# AST1080 register map
File version: 1.0
CPU: CM4 r0p1, little endian, MPU, FPU, 4 interrupt priority bits, 256 interrupts
Registers are 32-bit, read-write, reset 0x0 unless marked. A register's access mark holds for its fields unless they carry their own. Offsets are from the block's base; [hi:lo] are bit positions; {n}, {i} and the like mark numbered series.

## scu (part 1 of 2)
Base 0x74C02000
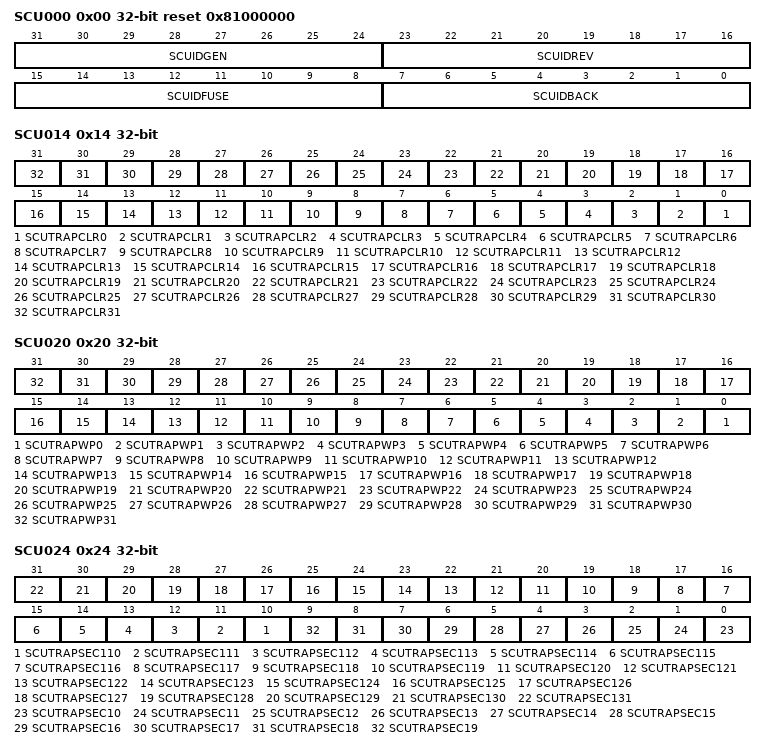
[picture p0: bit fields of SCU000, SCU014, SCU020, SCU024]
0x00 SCU000 reset 0x81000000 — Silicon Revision ID Register
  [31:24] SCUIDGEN ro, [23:16] SCUIDREV ro, [15:8] SCUIDFUSE ro, [7:0] SCUIDBACK ro
0x10 SCU010 — Hardware/OTP Strap 1 Register
  [n] SCUTRAP{n} (n=0..31)
  [8] SCUTRAP81 — SCU_TRAP_8
0x14 SCU014 — Hareware/OTP Strap Clear 1 Register
  [n] SCUTRAPCLR{n} (n=0..31)
0x20 SCU020 — Hardware/OTP Strap Write Protection 1 Register
  [n] SCUTRAPWP{n} (n=0..31)
0x24 SCU024 — Hardware/OTP Strap Secure Control Register 1
  [n-100] SCUTRAPSEC{n} (n=110..131), [n-10] SCUTRAPSEC{n} (n=10..19)
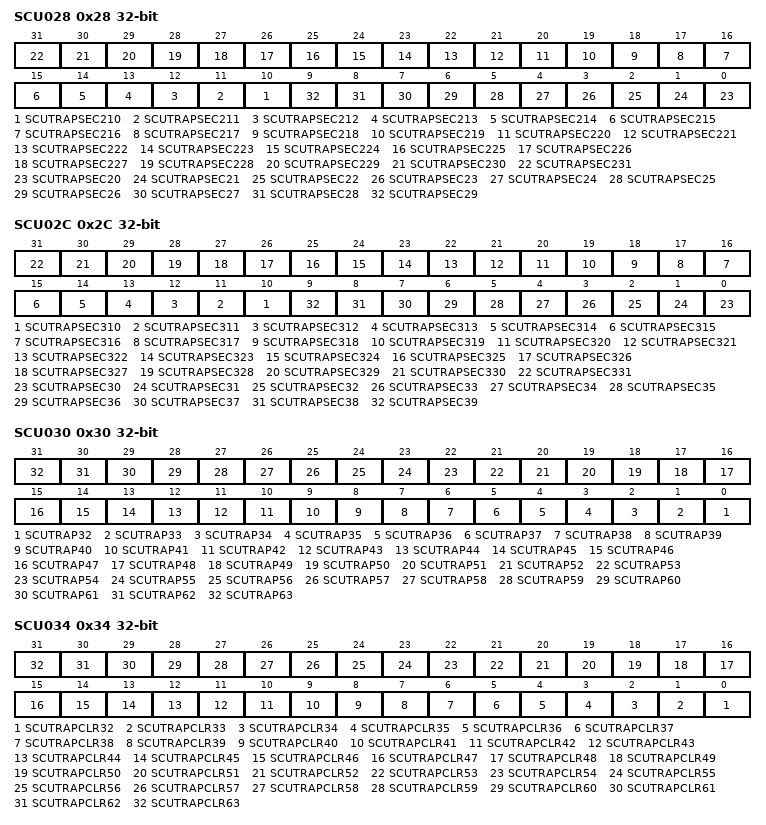
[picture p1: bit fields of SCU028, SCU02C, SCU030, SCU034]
0x28 SCU028 — Hardware/OTP Strap Secure Control Register 2
  [n-200] SCUTRAPSEC{n} (n=210..231), [n-20] SCUTRAPSEC{n} (n=20..29)
0x2C SCU02C — Hardware/OTP Strap Secure Control Register 3
  [n-300] SCUTRAPSEC{n} (n=310..331), [n-30] SCUTRAPSEC{n} (n=30..39)
0x30 SCU030 — Hardware/OTP Strap 2 Register
  [n-32] SCUTRAP{n} (n=32..63)
0x34 SCU034 — Hareware/OTP Strap Clear 2 Register
  [n-32] SCUTRAPCLR{n} (n=32..63)
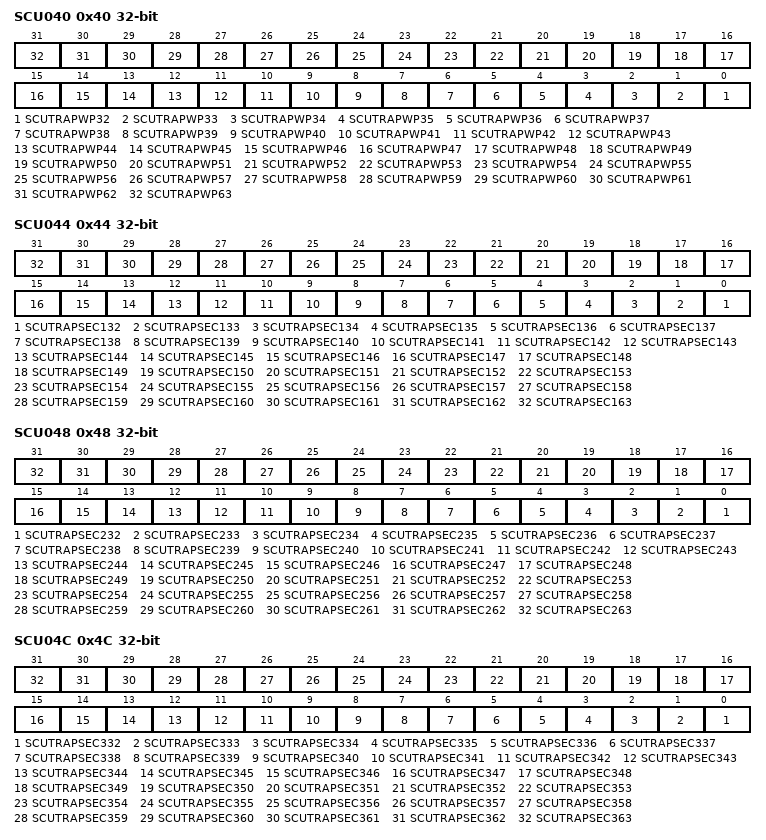
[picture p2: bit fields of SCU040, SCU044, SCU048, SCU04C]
0x40 SCU040 — Hardware/OTP Strap Write Protection 2 Register
  [n-32] SCUTRAPWP{n} (n=32..63)
0x44 SCU044 — Hardware/OTP Strap 2 Secure Control Register 1
  [n-132] SCUTRAPSEC{n} (n=132..163)
0x48 SCU048 — Hardware/OTP Strap 2 Secure Control Register 2
  [n-232] SCUTRAPSEC{n} (n=232..263)
0x4C SCU04C — Hardware/OTP Strap 2 Secure Control Register 3
  [n-332] SCUTRAPSEC{n} (n=332..363)
0x50 SCU050 — Hardware/OTP Strap 3 Register
  [n-64] SCUTRAP{n} (n=64..95)
  [20] SCUTRAP841 — SCU_TRAP_84
  [19] SCUTRAP831 — SCU_TRAP_83
  [18] SCUTRAP821 — SCU_TRAP_82
  [17] SCUTRAP811 — SCU_TRAP_81
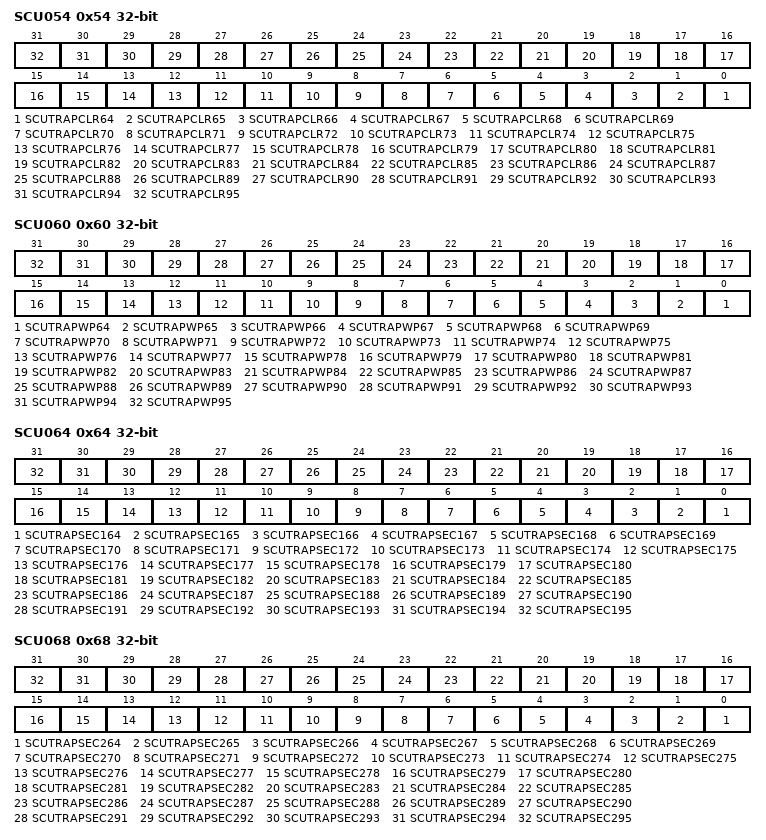
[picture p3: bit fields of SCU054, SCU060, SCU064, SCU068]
0x54 SCU054 — Hareware/OTP Strap Clear 3 Register
  [n-64] SCUTRAPCLR{n} (n=64..95)
0x60 SCU060 — Hardware/OTP Strap Write Protection 3 Register
  [n-64] SCUTRAPWP{n} (n=64..95)
0x64 SCU064 — Hardware/OTP Strap 3 Secure Control Register 1
  [n-164] SCUTRAPSEC{n} (n=164..195)
0x68 SCU068 — Hardware/OTP Strap 3 Secure Control Register 2
  [n-264] SCUTRAPSEC{n} (n=264..295)
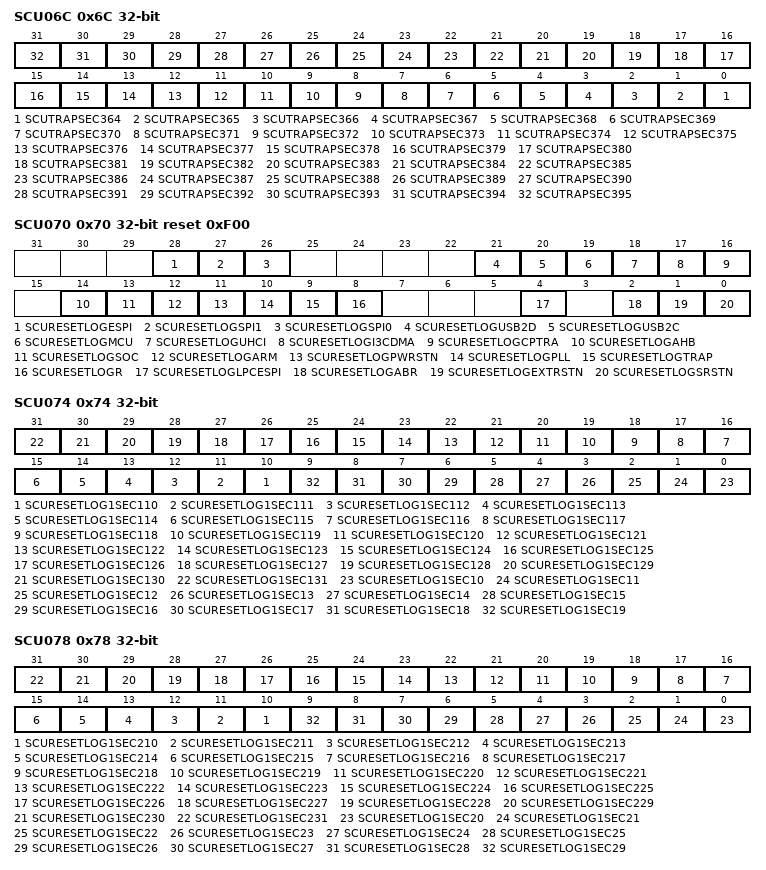
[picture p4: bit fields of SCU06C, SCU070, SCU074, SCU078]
0x6C SCU06C — Hardware/OTP Strap 3 Secure Control Register 3
  [n-364] SCUTRAPSEC{n} (n=364..395)
0x70 SCU070 reset 0xF00 (reset mask 0xC3F7F17) — System Reset Event Log Set 1 Register
  [28] SCURESETLOGESPI, [27] SCURESETLOGSPI1, [26] SCURESETLOGSPI0, [21] SCURESETLOGUSB2D, [20] SCURESETLOGUSB2C, [19] SCURESETLOGMCU, [18] SCURESETLOGUHCI, [17] SCURESETLOGI3CDMA, [16] SCURESETLOGCPTRA, [14] SCURESETLOGAHB, [13] SCURESETLOGSOC, [12] SCURESETLOGARM, [11] SCURESETLOGPWRSTN, [10] SCURESETLOGPLL, [9] SCURESETLOGTRAP, [8] SCURESETLOGR, [4] SCURESETLOGLPCESPI, [2] SCURESETLOGABR, [1] SCURESETLOGEXTRSTN, [0] SCURESETLOGSRSTN
0x74 SCU074 — System Reset Event Log Set 1 Secure Register 1
  [n-100] SCURESETLOG1SEC{n} (n=110..131), [n-10] SCURESETLOG1SEC{n} (n=10..19)
0x78 SCU078 — System Reset Event Log Set 1 Secure Register 2
  [n-200] SCURESETLOG1SEC{n} (n=210..231), [n-20] SCURESETLOG1SEC{n} (n=20..29)
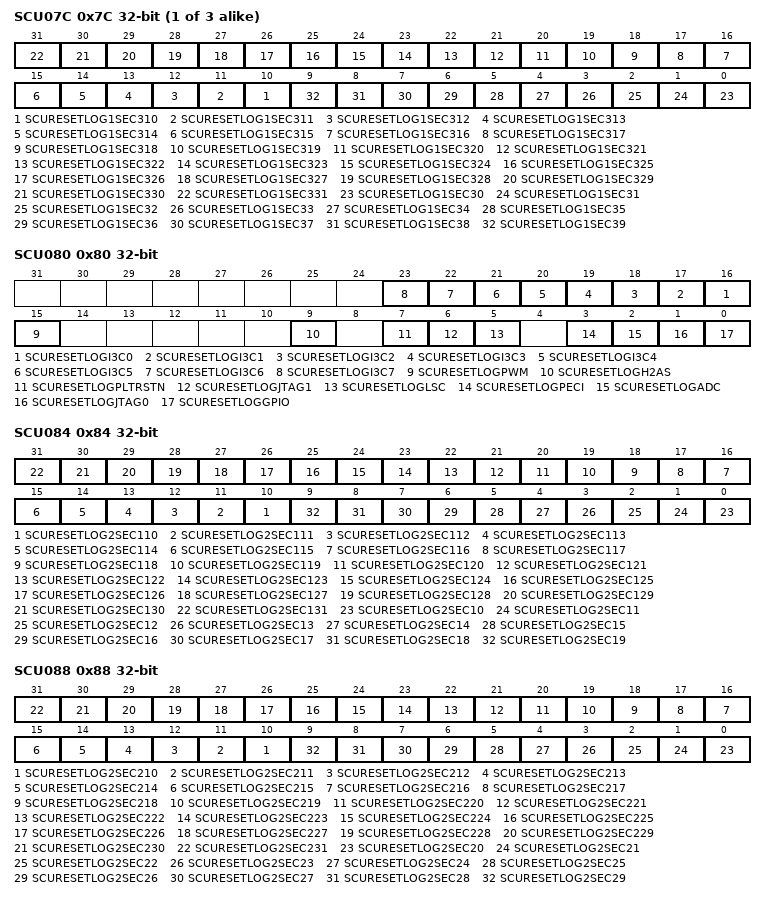
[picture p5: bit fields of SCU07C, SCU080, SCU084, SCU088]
{0xC+0x10*i} SCU{i:02}C (i=7..9) — System Reset Event Log Set {i-6} Secure Register 3
  [n-300] SCURESETLOG{i-6}SEC{n} (n=310..331), [n-30] SCURESETLOG{i-6}SEC{n} (n=30..39)
0x80 SCU080 (reset mask 0xFF0067) — System Reset Event Log Set 2 Register
  [n+16] SCURESETLOGI3C{n} (n=0..7), [15] SCURESETLOGPWM, [9] SCURESETLOGH2AS, [7] SCURESETLOGPLTRSTN, [6] SCURESETLOGJTAG1, [5] SCURESETLOGLSC, [3] SCURESETLOGPECI, [2] SCURESETLOGADC, [1] SCURESETLOGJTAG0, [0] SCURESETLOGGPIO
0x84 SCU084 — System Reset Event Log Set 2 Secure Register 1
  [n-100] SCURESETLOG2SEC{n} (n=110..131), [n-10] SCURESETLOG2SEC{n} (n=10..19)
0x88 SCU088 — System Reset Event Log Set 2 Secure Register 2
  [n-200] SCURESETLOG2SEC{n} (n=210..231), [n-20] SCURESETLOG2SEC{n} (n=20..29)
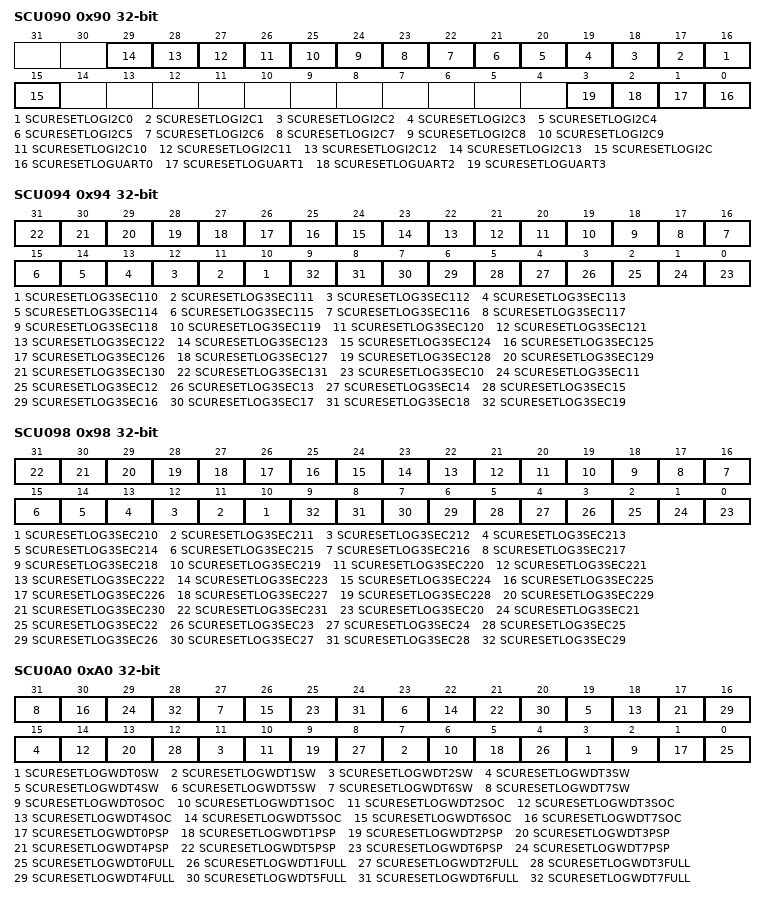
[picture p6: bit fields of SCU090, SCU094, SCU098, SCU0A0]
0x90 SCU090 — System Reset Event Log Set 3 Register
  [n+16] SCURESETLOGI2C{n} (n=0..13), [15] SCURESETLOGI2C, [n] SCURESETLOGUART{n} (n=0..3)
0x94 SCU094 — System Reset Event Log Set 3 Secure Register 1
  [n-100] SCURESETLOG3SEC{n} (n=110..131), [n-10] SCURESETLOG3SEC{n} (n=10..19)
0x98 SCU098 — System Reset Event Log Set 3 Secure Register 2
  [n-200] SCURESETLOG3SEC{n} (n=210..231), [n-20] SCURESETLOG3SEC{n} (n=20..29)
0xA0 SCU0A0 — System Reset Event Log Set 4 Register
  [4n+3] SCURESETLOGWDT{n}SW (n=0..7), [4n+2] SCURESETLOGWDT{n}SOC (n=0..7), [4n+1] SCURESETLOGWDT{n}PSP (n=0..7), [4n] SCURESETLOGWDT{n}FULL (n=0..7)
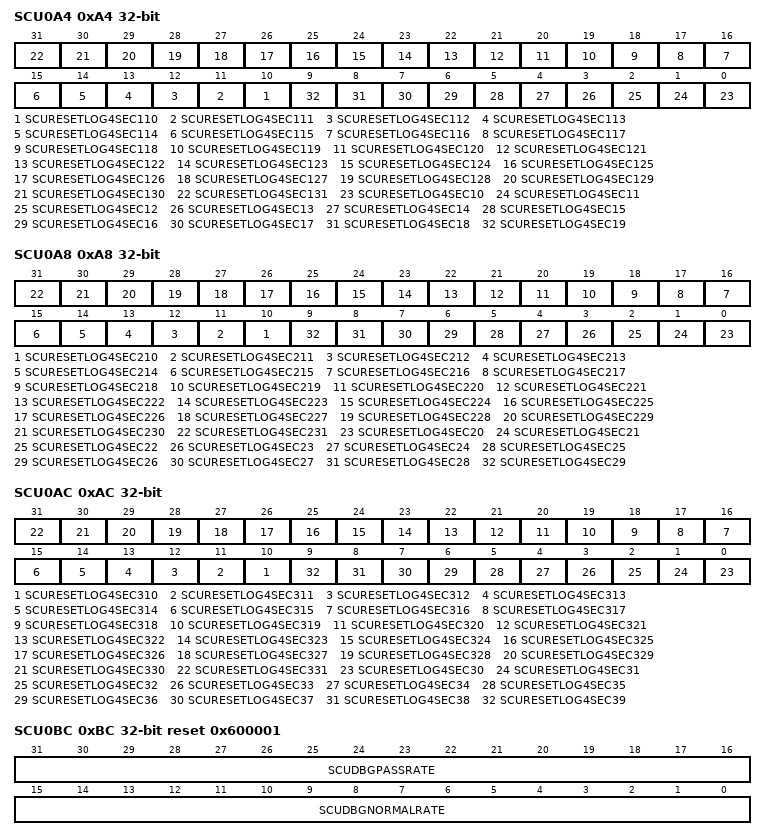
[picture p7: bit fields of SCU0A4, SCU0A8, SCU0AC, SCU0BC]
0xA4 SCU0A4 — System Reset Event Log Set 4 Secure Register 1
  [n-100] SCURESETLOG4SEC{n} (n=110..131), [n-10] SCURESETLOG4SEC{n} (n=10..19)
0xA8 SCU0A8 — System Reset Event Log Set 4 Secure Register 2
  [n-200] SCURESETLOG4SEC{n} (n=210..231), [n-20] SCURESETLOG4SEC{n} (n=20..29)
0xAC SCU0AC — System Reset Event Log Set 4 Secure Register 3
  [n-300] SCURESETLOG4SEC{n} (n=310..331), [n-30] SCURESETLOG4SEC{n} (n=30..39)
0xBC SCU0BC reset 0x600001 — Debug UART Baudrate
  [31:16] SCUDBGPASSRATE, [15:0] SCUDBGNORMALRATE
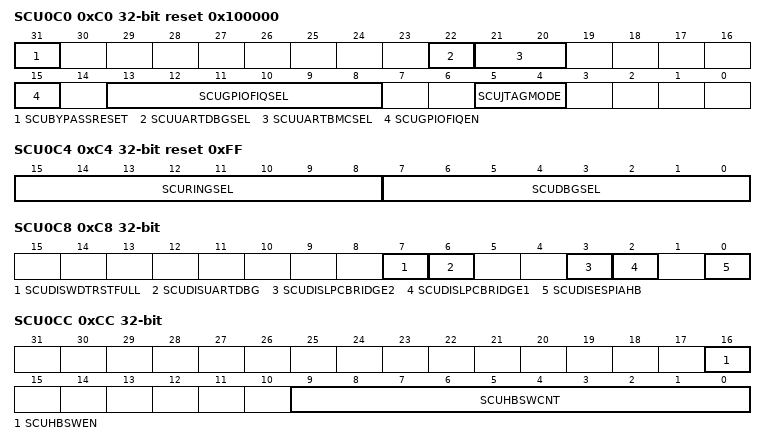
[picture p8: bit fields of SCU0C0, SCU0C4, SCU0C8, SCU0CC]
0xC0 SCU0C0 reset 0x100000 — Misc. Control Set 1 Register
  [31] SCUBYPASSRESET, [22] SCUUARTDBGSEL, [21:20] SCUUARTBMCSEL, [15] SCUGPIOFIQEN, [13:8] SCUGPIOFIQSEL, [5:4] SCUJTAGMODE
0xC4 SCU0C4 reset 0xFF — Debug Selection Register
  [15:8] SCURINGSEL, [7:0] SCUDBGSEL
0xC8 SCU0C8 — Debug Disable Register
  [7] SCUDISWDTRSTFULL, [6] SCUDISUARTDBG, [3] SCUDISLPCBRIDGE2, [2] SCUDISLPCBRIDGE1, [0] SCUDISESPIAHB
0xCC SCU0CC — HeartBeat Control Register
  [16] SCUHBSWEN, [9:0] SCUHBSWCNT
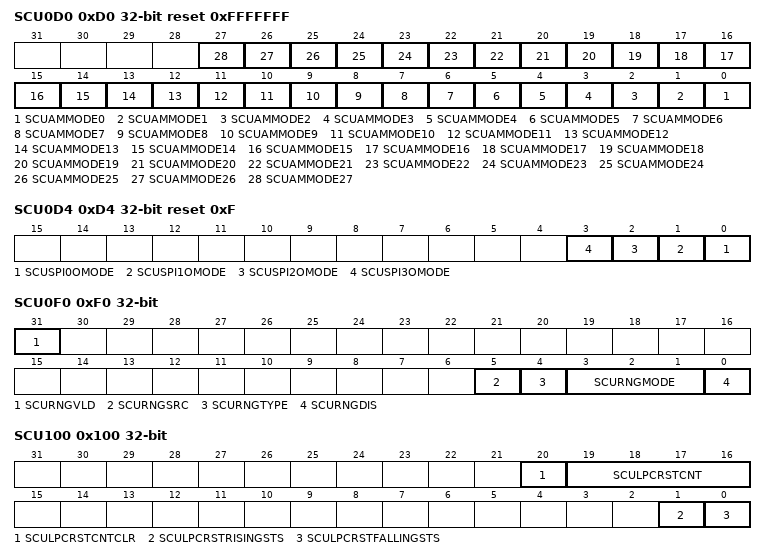
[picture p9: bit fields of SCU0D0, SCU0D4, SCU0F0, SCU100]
0xD0 SCU0D0 reset 0xFFFFFFF — Analog Mux Mode Register
  [n] SCUAMMODE{n} (n=0..27)
0xD4 SCU0D4 reset 0xF — SPI Mode Register
  [n] SCUSPI{n}OMODE (n=0..3)
0xF0 SCU0F0 — Random Number Generator Control Register
  [31] SCURNGVLD ro, [5] SCURNGSRC, [4] SCURNGTYPE, [3:1] SCURNGMODE, [0] SCURNGDIS
0xF4 SCU0F4 — Random Number Generator Data Register
  [31:0] SCURNGDAT ro
0x100 SCU100 — Interrupt Status Register
  [20] SCULPCRSTCNTCLR, [19:16] SCULPCRSTCNT ro, [1] SCULPCRSTRISINGSTS, [0] SCULPCRSTFALLINGSTS
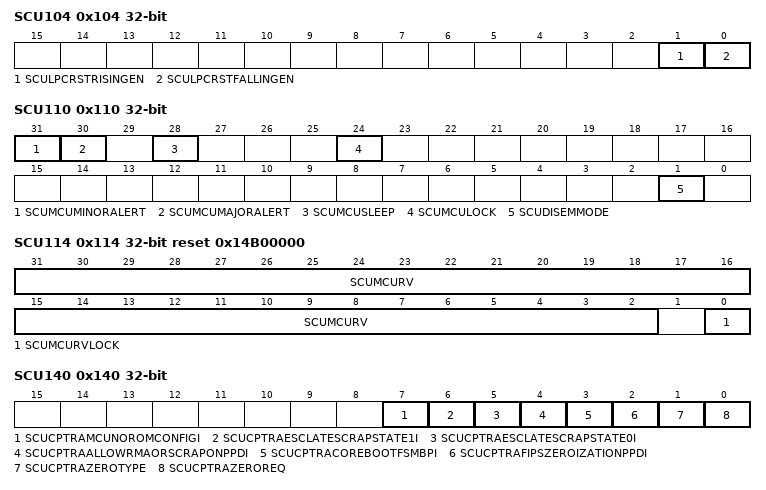
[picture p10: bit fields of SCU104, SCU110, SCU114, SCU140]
0x104 SCU104 — Interrupt Control Register
  [1] SCULPCRSTRISINGEN, [0] SCULPCRSTFALLINGEN
0x110 SCU110 — MCU Control and Status Register
  [31] SCUMCUMINORALERT ro, [30] SCUMCUMAJORALERT ro, [28] SCUMCUSLEEP ro, [24] SCUMCULOCK, [1] SCUDISEMMODE
0x114 SCU114 reset 0x14B00000 — MCU Reset Vector
  [31:2] SCUMCURV, [0] SCUMCURVLOCK
0x120 SCU120 — CPTRA Page Register 0
  [31:16] SCUCPTRAPAGEADR0
0x124 SCU124 — CPTRA Page Register 1
  [31:16] SCUCPTRAPAGEADR1
0x128 SCU128 — CPTRA Page Register 2
  [31:16] SCUCPTRAPAGEADR2
0x12C SCU12C — CPTRA Page Register 3
  [31:16] SCUCPTRAPAGEADR3
0x130 SCU130 — CPTRA Page Register 4
  [31:16] SCUCPTRAPAGEADR4
0x134 SCU134 — CPTRA Page Register 5
  [31:16] SCUCPTRAPAGEADR5
0x140 SCU140 — Caliptra Config Register 0
  [7] SCUCPTRAMCUNOROMCONFIGI, [6] SCUCPTRAESCLATESCRAPSTATE1I, [5] SCUCPTRAESCLATESCRAPSTATE0I, [4] SCUCPTRAALLOWRMAORSCRAPONPPDI, [3] SCUCPTRACOREBOOTFSMBPI, [2] SCUCPTRAFIPSZEROIZATIONPPDI, [1] SCUCPTRAZEROTYPE, [0] SCUCPTRAZEROREQ
0x144 SCU144 — Caliptra Config Register 1
  [31:0] SCUCPTRASTRAPPRODDEBUG
0x148 SCU148 — Caliptra Config Register 2
  [31:0] SCUCPTRASTRAPNUMDEBUG
0x14C SCU14C — Caliptra Config Register 3
  [31:0] SCUCPTRACOREGENERICINPUT0
0x150 SCU150 — Caliptra Config Register 4
  [31:0] SCUCPTRACOREGENERICINPUT1
0x154 SCU154 — Caliptra Config Register 5
  [31:0] SCUCPTRAMCIGENERICINPUT0
0x158 SCU158 — Caliptra Config Register 6
  [31:0] SCUCPTRAMCIGENERICINPUT1
0x15C SCU15C — Caliptra Config Register 7
  [31:0] SCUCPTRAMCIGENERICOUTPUT0 ro
0x160 SCU160 — Caliptra Config Register 8
  [31:0] SCUCPTRAMCIGENERICOUTPUT1 ro
0x180 SCU180 — SCU\_CPU\_SCRATCH\_1
  [31:0] SCUSCRATCH1
0x184 SCU184 — SCU\_CPU\_SCRATCH\_2
  [31:0] SCUSCRATCH2
0x188 SCU188 — SCU\_CPU\_SCRATCH\_3
  [31:0] SCUSCRATCH3
0x18C SCU18C — SCU\_CPU\_SCRATCH\_4
  [31:0] SCUSCRATCH4
0x190 SCU190 — SCU\_CPU\_SCRATCH\_5
  [31:0] SCUSCRATCH5
0x194 SCU194 — SCU\_CPU\_SCRATCH\_6
  [31:0] SCUSCRATCH6
0x198 SCU198 — SCU\_CPU\_SCRATCH\_7
  [31:0] SCUSCRATCH7
0x19C SCU19C — SCU\_CPU\_SCRATCH\_8
  [31:0] SCUSCRATCH8
0x1A0 SCU1A0 — SCU\_CPU\_SCRATCH\_9
  [31:0] SCUSCRATCH9
0x1A4 SCU1A4 — SCU\_CPU\_SCRATCH\_10
  [31:0] SCUSCRATCH10
0x1A8 SCU1A8 — SCU\_CPU\_SCRATCH\_11
  [31:0] SCUSCRATCH11
0x1AC SCU1AC — SCU\_CPU\_SCRATCH\_12
  [31:0] SCUSCRATCH12
0x1B0 SCU1B0 — SCU\_CPU\_SCRATCH\_13
  [31:0] SCUSCRATCH13
0x1B4 SCU1B4 — SCU\_CPU\_SCRATCH\_14
  [31:0] SCUSCRATCH14
0x1B8 SCU1B8 — SCU\_CPU\_SCRATCH\_15
  [31:0] SCUSCRATCH15
0x1BC SCU1BC — SCU\_CPU\_SCRATCH\_16
  [31:0] SCUSCRATCH16
0x1C0 SCU1C0 — SCU\_CPU\_SCRATCH\_17
  [31:0] SCUSCRATCH17
0x1C4 SCU1C4 — SCU\_CPU\_SCRATCH\_18
  [31:0] SCUSCRATCH18
0x1C8 SCU1C8 — SCU\_CPU\_SCRATCH\_19
  [31:0] SCUSCRATCH19
0x1CC SCU1CC — SCU\_CPU\_SCRATCH\_20
  [31:0] SCUSCRATCH20
0x1D0 SCU1D0 — SCU\_CPU\_SCRATCH\_21
  [31:0] SCUSCRATCH21
0x1D4 SCU1D4 — SCU\_CPU\_SCRATCH\_22
  [31:0] SCUSCRATCH22
0x1D8 SCU1D8 — SCU\_CPU\_SCRATCH\_23
  [31:0] SCUSCRATCH23
0x1DC SCU1DC — SCU\_CPU\_SCRATCH\_24
  [31:0] SCUSCRATCH24
0x1E0 SCU1E0 — SCU\_CPU\_SCRATCH\_25
  [31:0] SCUSCRATCH25
0x1E4 SCU1E4 — SCU\_CPU\_SCRATCH\_26
  [31:0] SCUSCRATCH26
0x1E8 SCU1E8 — SCU\_CPU\_SCRATCH\_27
  [31:0] SCUSCRATCH27
0x1EC SCU1EC — SCU\_CPU\_SCRATCH\_28
  [31:0] SCUSCRATCH28
0x1F0 SCU1F0 — SCU\_CPU\_SCRATCH\_29
  [31:0] SCUSCRATCH29
0x1F4 SCU1F4 — SCU\_CPU\_SCRATCH\_30
  [31:0] SCUSCRATCH30
0x1F8 SCU1F8 — SCU\_CPU\_SCRATCH\_31
  [31:0] SCUSCRATCH31
0x1FC SCU1FC — SCU\_CPU\_SCRATCH\_32
  [31:0] SCUSCRATCH32
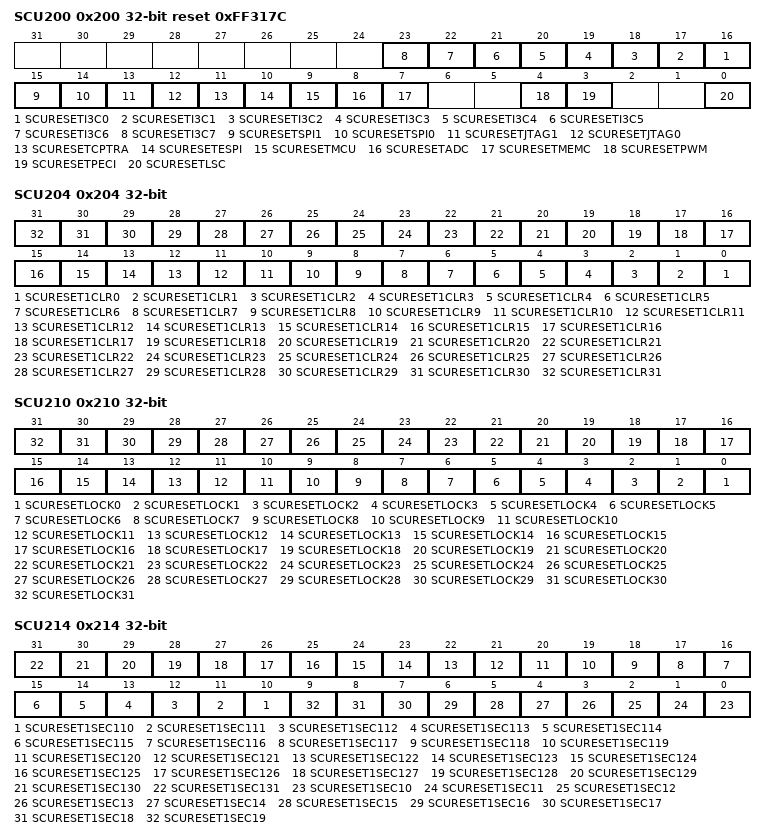
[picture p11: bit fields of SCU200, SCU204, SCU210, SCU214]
0x200 SCU200 reset 0xFF317C (reset mask 0xFFFB81) — System Reset Control 1 Register
  [n+16] SCURESETI3C{n} (n=0..7), [15] SCURESETSPI1, [14] SCURESETSPI0, [13] SCURESETJTAG1, [12] SCURESETJTAG0, [11] SCURESETCPTRA, [10] SCURESETESPI, [9] SCURESETMCU, [8] SCURESETADC, [7] SCURESETMEMC, [4] SCURESETPWM, [3] SCURESETPECI, [0] SCURESETLSC
0x204 SCU204 — System Reset Clear 1 Register
  [n] SCURESET1CLR{n} (n=0..31)
0x210 SCU210 — System Reset Lock 1 Register
  [n] SCURESETLOCK{n} (n=0..31)
0x214 SCU214 — System Reset Secure 1 Register 1
  [n-100] SCURESET1SEC{n} (n=110..131), [n-10] SCURESET1SEC{n} (n=10..19)
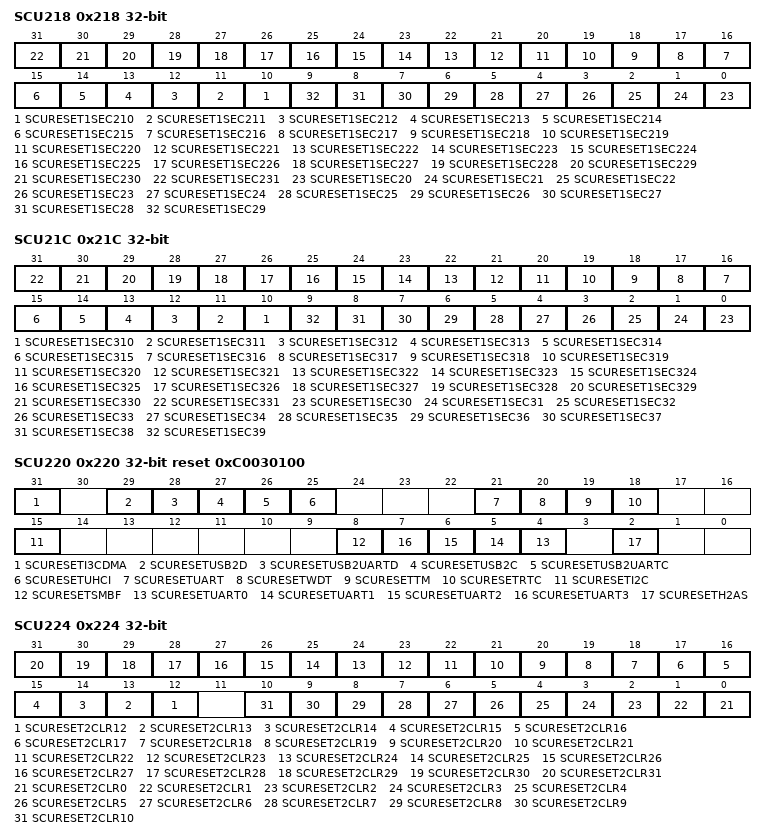
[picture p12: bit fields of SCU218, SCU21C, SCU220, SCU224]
0x218 SCU218 — System Reset Secure 1 Register 2
  [n-200] SCURESET1SEC{n} (n=210..231), [n-20] SCURESET1SEC{n} (n=20..29)
0x21C SCU21C — System Reset Secure 1 Register 3
  [n-300] SCURESET1SEC{n} (n=310..331), [n-30] SCURESET1SEC{n} (n=30..39)
0x220 SCU220 reset 0xC0030100 (reset mask 0xBE3C80F0) — System Reset Control 2 Register
  [31] SCURESETI3CDMA, [29] SCURESETUSB2D, [28] SCURESETUSB2UARTD, [27] SCURESETUSB2C, [26] SCURESETUSB2UARTC, [25] SCURESETUHCI, [21] SCURESETUART, [20] SCURESETWDT, [19] SCURESETTM, [18] SCURESETRTC, [15] SCURESETI2C, [8] SCURESETSMBF, [n+4] SCURESETUART{n} (n=0..3), [2] SCURESETH2AS
0x224 SCU224 — System Reset Clear 2 Register
  [n] SCURESET2CLR{n} (n=12..31), [n] SCURESET2CLR{n} (n=0..10)
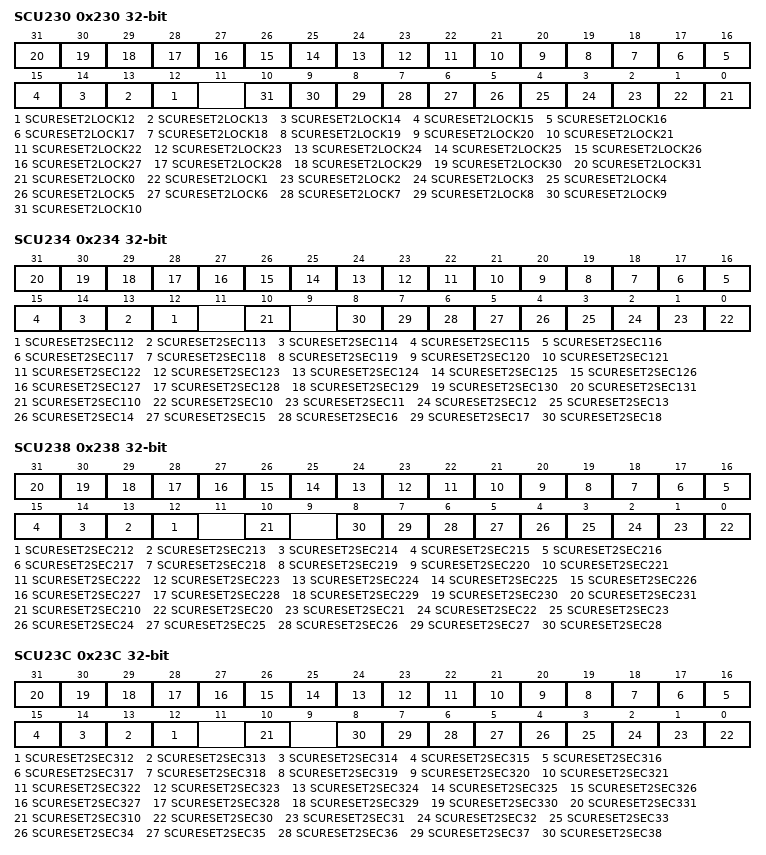
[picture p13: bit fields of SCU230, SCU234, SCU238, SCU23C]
0x230 SCU230 — System Reset Lock 2 Register
  [n] SCURESET2LOCK{n} (n=12..31), [n] SCURESET2LOCK{n} (n=0..10)
0x234 SCU234 — System Reset Secure 2 Register 1
  [n-100] SCURESET2SEC{n} (n=112..131), [10] SCURESET2SEC110, [n-10] SCURESET2SEC{n} (n=10..18)
0x238 SCU238 — System Reset Secure 2 Register 2
  [n-200] SCURESET2SEC{n} (n=212..231), [10] SCURESET2SEC210, [n-20] SCURESET2SEC{n} (n=20..28)
0x23C SCU23C — System Reset Secure 2 Register 3
  [n-300] SCURESET2SEC{n} (n=312..331), [10] SCURESET2SEC310, [n-30] SCURESET2SEC{n} (n=30..38)
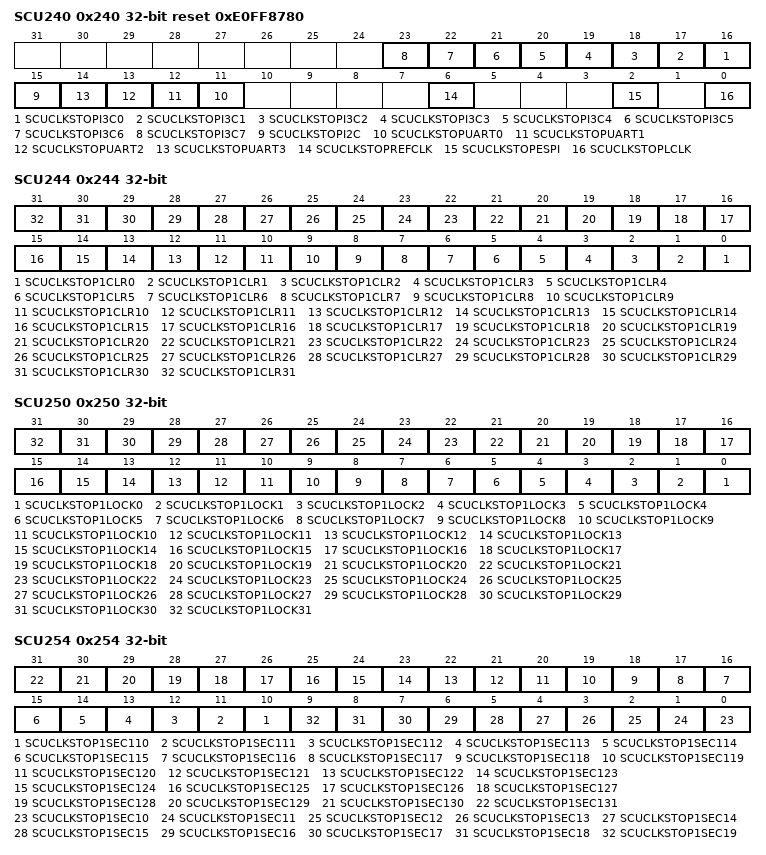
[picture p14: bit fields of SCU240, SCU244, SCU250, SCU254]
0x240 SCU240 reset 0xE0FF8780 (reset mask 0xFFF841) — Clock Stop Control 1 Register
  [n+16] SCUCLKSTOPI3C{n} (n=0..7), [15] SCUCLKSTOPI2C, [n+11] SCUCLKSTOPUART{n} (n=0..3), [6] SCUCLKSTOPREFCLK, [2] SCUCLKSTOPESPI, [0] SCUCLKSTOPLCLK
0x244 SCU244 — Clock Stop Clear 1 Register
  [n] SCUCLKSTOP1CLR{n} (n=0..31)
0x250 SCU250 — Clock Stop Lock 1 Register
  [n] SCUCLKSTOP1LOCK{n} (n=0..31)
0x254 SCU254 — Clock Stop Secure 1 Register 1
  [n-100] SCUCLKSTOP1SEC{n} (n=110..131), [n-10] SCUCLKSTOP1SEC{n} (n=10..19)
0x258 SCU258 — Clock Stop Secure 1 Register 2
  [n-200] SCUCLKSTOP1SEC{n} (n=210..231), [n-20] SCUCLKSTOP1SEC{n} (n=20..29)
0x25C SCU25C — Clock Stop Secure 1 Register 3
  [n-300] SCUCLKSTOP1SEC{n} (n=310..331), [n-30] SCUCLKSTOP1SEC{n} (n=30..39)
0x260 SCU260 reset 0x1070 — Clock Stop Control 2 Register
  [18] SCUCLKSTOPUSB2D, [17] SCUCLKSTOPUSB2C, [12] SCUCLKSTOPUHCI, [n-5] SCUCLKSTOPUART{n} (n=5..12)
0x264 SCU264 — Clock Stop Clear 2 Register
  [n] SCUCLKSTOP2CLR{n} (n=0..19)
0x270 SCU270 — Clock Stop Lock 2 Register
  [n] SCUCLKSTOP2LOCK{n} (n=0..19)
0x274 SCU274 — Clock Stop Secure 2 Register 1
  [n-100] SCUCLKSTOP2SEC{n} (n=110..119), [n-10] SCUCLKSTOP2SEC{n} (n=10..19)
0x278 SCU278 — Clock Stop Secure 2 Register 2
  [n-200] SCUCLKSTOP2SEC{n} (n=210..219), [n-20] SCUCLKSTOP2SEC{n} (n=20..29)
0x27C SCU27C — Clock Stop Secure 2 Register 3
  [n-300] SCUCLKSTOP2SEC{n} (n=310..319), [n-30] SCUCLKSTOP2SEC{n} (n=30..39)
0x280 SCU280 reset 0x104000 — Clock Selection 1 Register
  [20:18] SCUPCLKDIV, [16:14] SCUMEMCLKDIV, [13] SCUUARTDBCLKSEL, [n] SCUUART{n}CLKSEL (n=0..12)
0x284 SCU284 reset 0x92301480 — Clock Selection 2 Register
  [31:29] SCUSPIS1CLKDIV, [28:26] SCUSPIS0CLKDIV, [25:23] SCUI3CCLKDIV, [22:20] SCUHCLKDIV, [17] SCURTCDIV, [16] SCUPECICLKSEL, [14:12] SCUCPTRACLKDIV, [10:8] SCUSSPCLKDIV, [7:5] SCUPSPCLKDIV, [4:3] SCUHUXCLKSEL, [1:0] SCUUXCLKSEL
0x2A0 SCU2A0 — Clock Selection Lock 1 Register
  [29] SCUCLKSEL1LOCK29, [25] SCUCLKSEL1LOCK25, [21] SCUCLKSEL1LOCK21, [18] SCUCLKSEL1LOCK18, [n] SCUCLKSEL1LOCK{n} (n=0..14)
0x2A4 SCU2A4 — Clock Selection Secure 1 Register 1
  [29] SCUCLKSEL1SEC129, [25] SCUCLKSEL1SEC125, [21] SCUCLKSEL1SEC121, [18] SCUCLKSEL1SEC118, [n-100] SCUCLKSEL1SEC{n} (n=110..114), [n-10] SCUCLKSEL1SEC{n} (n=10..19)
0x2A8 SCU2A8 — Clock Selection Secure 1 Register 2
  [29] SCUCLKSEL1SEC229, [25] SCUCLKSEL1SEC225, [21] SCUCLKSEL1SEC221, [18] SCUCLKSEL1SEC218, [n-200] SCUCLKSEL1SEC{n} (n=210..214), [n-20] SCUCLKSEL1SEC{n} (n=20..29)
0x2AC SCU2AC — Clock Selection Secure 1 Register 3
  [31] SCUCLKSEL1SEC331 ro, [30] SCUCLKSEL1SEC330 ro, [29] SCUCLKSEL1SEC329, [28] SCUCLKSEL1SEC328 ro, [27] SCUCLKSEL1SEC327 ro, [26] SCUCLKSEL1SEC326 ro, [25] SCUCLKSEL1SEC325, [24] SCUCLKSEL1SEC324 ro, [23] SCUCLKSEL1SEC323 ro, [22] SCUCLKSEL1SEC322 ro, [21] SCUCLKSEL1SEC321, [20] SCUCLKSEL1SEC320 ro, [19] SCUCLKSEL1SEC319 ro, [18] SCUCLKSEL1SEC318, [17] SCUCLKSEL1SEC317 ro, [16] SCUCLKSEL1SEC316 ro, [15] SCUCLKSEL1SEC315 ro, [n-300] SCUCLKSEL1SEC{n} (n=310..314), [n-30] SCUCLKSEL1SEC{n} (n=30..39)
0x2B0 SCU2B0 — Clock Selection Lock 2 Register
  [23] SCUCLKSEL2LOCK23, [n] SCUCLKSEL2LOCK{n} (n=15..20), [12] SCUCLKSEL2LOCK12, [8] SCUCLKSEL2LOCK8, [5] SCUCLKSEL2LOCK5, [3] SCUCLKSEL2LOCK3, [0] SCUCLKSEL2LOCK0
0x2B4 SCU2B4 — Clock Selection Secure 2 Register 1
  [23] SCUCLKSEL2SEC123, [n-100] SCUCLKSEL2SEC{n} (n=115..120), [12] SCUCLKSEL2SEC112, [8] SCUCLKSEL2SEC18, [5] SCUCLKSEL2SEC15, [3] SCUCLKSEL2SEC13, [0] SCUCLKSEL2SEC10
0x2B8 SCU2B8 — Clock Selection Secure 2 Register 2
  [23] SCUCLKSEL2SEC223, [n-200] SCUCLKSEL2SEC{n} (n=215..220), [12] SCUCLKSEL2SEC212, [8] SCUCLKSEL2SEC28, [5] SCUCLKSEL2SEC25, [3] SCUCLKSEL2SEC23, [0] SCUCLKSEL2SEC20
0x2BC SCU2BC — Clock Selection Secure 2 Register 3
  [23] SCUCLKSEL2SEC323, [n-300] SCUCLKSEL2SEC{n} (n=315..320), [12] SCUCLKSEL2SEC312, [8] SCUCLKSEL2SEC38, [5] SCUCLKSEL2SEC35, [3] SCUCLKSEL2SEC33, [0] SCUCLKSEL2SEC30
0x2F0 SCU2F0 reset 0x19EC (reset mask 0xFF7901) — EXTRST\# Reset Selection 1 Register
  [n+16] SCURESETEXTI3C{n} (n=0..7), [14] SCURESETEXTSPI1, [13] SCURESETEXTSPI0, [12] SCURESETEXTJTAG1, [11] SCURESETEXTJTAG0, [10] SCURESETEXTESPI, [8] SCURESETEXTADC, [4] SCURESETEXTPWM, [3] SCURESETEXTPECI, [0] SCURESETEXTLPC
0x2F4 SCU2F4 reset 0x2010E803 (reset mask 0xA010F8F7) — EXTRST\# Reset Selection 2 Register
  [31] SCURESETEXTI3CDMA, [29] SCURESETEXTCPTRA, [20] SCURESETEXTMCU, [15] SCURESETEXTUART, [14] SCURESETEXTWDT, [13] SCURESETEXTTM, [12] SCURESETEXTRTC, [11] SCURESETEXTGPIO, [9] SCURESETEXTH2AS, [8] SCURESETEXTI2CF, [n+4] SCURESETEXTUART{n} (n=0..3), [2] SCURESETEXTAHB, [1] SCURESETEXTSOC, [0] SCURESETEXTCPU
0x2F8 SCU2F8 reset 0x3E0000 — EXTRST\# Reset Selection 3 Register
  [21] SCURESETEXTUSB2D, [20] SCURESETEXTUSB2UARTD, [19] SCURESETEXTUSB2C, [18] SCURESETEXTUSB2UARTC, [17] SCURESETEXTUHCI, [n+1] SCURESETEXTI2C{n} (n=0..13), [0] SCURESETEXTI2C
0x300 SCU300 reset 0x1000004F — HPLL Parameter Register
  [28] SCUHPLLENSAT, [27] SCUHPLLFAST, [26] SCUHPLLTEST, [25] SCUHPLLRESET, [24] SCUHPLLBYPASS, [23] SCUHPLLOFF, [22:19] SCUHPLLPOST, [18:13] SCUHPLLDENUM, [12:0] SCUHPLLNUM
0x304 SCU304 reset 0x27 — HPLL Extended Parameter Register
  [31] SCUHPLLLOCK ro, [11:0] SCUHPLLBWADJ
0x310 SCU310 reset 0x6020 — DIPLL Parameter Register
  [27:19] SCUDIPLLLPF, [18] SCUDIPLLDCOCONEN, [17:9] SCUDIPLLDIVN, [8:5] SCUDIPLLDIVPRE, [4] SCUDIPLLCHGEN, [3] SCUDIPLLSSCEN, [2] SCUDIPLLFNMODE, [1] SCUDIPLLDCOEN, [0] SCUDIPLLEN
0x314 SCU314 — DIPLL Parameter Register 2
  [31:16] SCUDIPLLMS, [9:0] SCUDIPLLMP
0x318 SCU318 — DIPLL Parameter Register 3
  [26:0] SCUDIPLLFOFF
0x31C SCU31C reset 0x3 — DIPLL Parameter Register 4
  [13] SCUDIPLLBYPASSEN, [12:9] SCUDIPLLDBGSEL, [8] SCUDIPLLDBGEN, [7] SCUDIPLLMOLPFEN, [6] SCUDIPLLSPREADEN, [5:1] SCUDIPLLDIVPOST, [0] SCUDIPLLDIVPOSTEN
0x320 SCU320 reset 0x156 — DIPLL Parameter Register 5
  [17] SCUDIPLLFASTLOCKEN, [16] SCUDIPLLDEN, [15] SCUDIPLLFHEN, [14:12] SCUDIPLLFDDIV, [11:10] SCUDIPLLFMTOR, [9] SCUDIPLLFMEN, [8] SCUDIPLLRTDLY, [7:6] SCUDIPLLKI, [5] SCUDIPLLDIVNSEL, [4] SCUDIPLLDIVSYS, [3:0] SCUDIPLLBWCON
0x324 SCU324 — DIPLL Parameter Register 6
  [17:0] SCUDIPLLFHMS
0x32C SCU32C — DIPLL Parameter Register 8
  [26:19] SCUDIPLLDBGOUT ro, [18] SCUDIPLLFHRDY ro, [17] SCUDIPLLRDYTYPE1 ro, [16] SCUDIPLLFMRDY ro, [15] SCUDIPLLFMUNDER ro, [14] SCUDIPLLFMOVER ro, [13:5] SCUDIPLLLPFOUT ro, [4:2] SCUDIPLLLOCKDET ro, [1] SCUDIPLLRDYGAIN ro, [0] SCUDIPLLRDYCLK ro
0x330 SCU330 reset 0x14503 — UARTCLK Generation Register
  [17:8] SCUUXN, [7:0] SCUUXR
0x334 SCU334 reset 0x14560 — HUARTCLK Generation Register
  [17:8] SCUHUXN, [7:0] SCUHUXR
0x380 SCU380 — Clock Duty Measurement Control Register
  [16] SCUDUTYDONERGMII ro, [6:4] SCUDUTYRESULTSEL, [3] SCUDUTYSTART, [2:1] SCUDUTYRINGSEL, [0] SCUDUTYRINGEN
0x384 SCU384 — Clock Duty Selection Register
  [14:8] SCUDUTYSELRGMII
0x388 SCU388 — Clock Duty Measurement Result Register
  [31:16] SCUDUTYNVALUE ro, [15:0] SCUDUTYPVALUE ro
0x390 SCU390 — MAC0/1 Interface Clock Delay Setting
  [29] SCUMACRMIIRCLKOE, [26] SCUMACRMIIFALLING, [24] SCUMACRXCLKINVERSE, [17:12] SCUMACRXCLKINPUTDELAY, [5:0] SCUMACTXCLKOUTPUTDELAY
0x394 SCU394 — MAC0/1 Interface Clock Delay 100M Setting
  [24] SCUMACRXCLK100MINVERSE, [17:12] SCUMACRXCLK100MINPUTDELAY, [5:0] SCUMACTXCLK100MOUTPUTDELAY
0x398 SCU398 — MAC0/1 Interface Clock Delay 10M Setting
  [24] SCUMACRXCLK10MINVERSE, [17:12] SCUMACRXCLK10MINPUTDELAY, [5:0] SCUMACTXCLK10MOUTPUTDELAY
0x3A0 SCU3A0 — Frequency Counter Control Register
  [29:16] SCUFREQCOUNTER ro, [14:9] SCUFREQRINGSTG, [8] SCUFREQOE, [7] SCUFREQRESULT ro, [6] SCUFREQDONE ro, [5:2] SCUFREQSELECT, [1] SCUFREQOSCEN, [0] SCUFREQRINGEN
0x3A4 SCU3A4 — Frequency Counter Comparison
  [29:16] SCUFREQUPPER, [13:0] SCUFREQLOWER
0x3B0 SCU3B0 reset 0xA — USB Controler Register
  [3:2] SCUUSBDSEL, [1:0] SCUUSBCSEL
0x3B4 SCU3B4 — USB Controler Lock Register
  [2] SCUUSBLOCK2, [0] SCUUSBLOCK0
0x3B8 SCU3B8 — USB Controler Secure Register 1
  [2] SCUUSBSEC12, [0] SCUUSBSEC10
0x3BC SCU3BC — USB Controler Secure Register 2
  [2] SCUUSBSEC22, [0] SCUUSBSEC20
0x3C0 SCU3C0 — USB Controler Secure Register 3
  [2] SCUUSBSEC32, [0] SCUUSBSEC30
0x400 SCU400 — Multi-Function Pin Control \#1
  [4n+2:4n] SCUMUXIO{n:03} (n=0..7)
0x404 SCU404 — Multi-Function Pin Control \#2
  [4n-30:4n-32] SCUMUXIO{n:03} (n=8..15)
0x408 SCU408 — Multi-Function Pin Control \#3
  [4n-62:4n-64] SCUMUXIO{n:03} (n=16..23)
0x40C SCU40C — Multi-Function Pin Control \#4
  [4n-94:4n-96] SCUMUXIO{n:03} (n=24..31)
0x410 SCU410 — Multi-Function Pin Control \#5
  [4n-126:4n-128] SCUMUXIO{n:03} (n=32..39)
0x414 SCU414 reset 0x110000 — Multi-Function Pin Control \#6
  [4n-158:4n-160] SCUMUXIO{n:03} (n=40..47)
0x418 SCU418 — Multi-Function Pin Control \#7
  [4n-190:4n-192] SCUMUXIO{n:03} (n=48..55)
0x41C SCU41C — Multi-Function Pin Control \#8
  [4n-222:4n-224] SCUMUXIO{n:03} (n=56..63)
0x420 SCU420 — Multi-Function Pin Control \#9
  [4n-254:4n-256] SCUMUXIO{n:03} (n=64..71)
0x424 SCU424 — Multi-Function Pin Control \#10
  [4n-286:4n-288] SCUMUXIO{n:03} (n=72..79)
0x428 SCU428 — Multi-Function Pin Control \#11
  [4n-318:4n-320] SCUMUXIO{n:03} (n=80..87)
0x42C SCU42C — Multi-Function Pin Control \#12
  [4n-350:4n-352] SCUMUXIO{n:03} (n=88..95)
0x430 SCU430 — Multi-Function Pin Control \#13
  [4n-382:4n-384] SCUMUXIO{n:03} (n=96..103)
0x434 SCU434 — Multi-Function Pin Control \#14
  [4n-414:4n-416] SCUMUXIO{n} (n=104..111)
0x438 SCU438 — Multi-Function Pin Control \#15
  [4n-446:4n-448] SCUMUXIO{n} (n=112..119)
0x43C SCU43C reset 0x11000000 — Multi-Function Pin Control \#16
  [4n-478:4n-480] SCUMUXIO{n} (n=120..127)
0x440 SCU440 reset 0x22111111 — Multi-Function Pin Control \#17
  [4n-510:4n-512] SCUMUXIO{n} (n=128..135)
0x444 SCU444 reset 0x222 — Multi-Function Pin Control \#18
  [4n-542:4n-544] SCUMUXIO{n} (n=136..143)
0x448 SCU448 — Multi-Function Pin Control \#19
  [4n-574:4n-576] SCUMUXIO{n} (n=144..151)
0x44C SCU44C — Multi-Function Pin Control \#20
  [4n-606:4n-608] SCUMUXIO{n} (n=152..159)
0x450 SCU450 reset 0x11200000 — Multi-Function Pin Control \#21
  [4n-638:4n-640] SCUMUXIO{n} (n=160..167)
0x454 SCU454 reset 0x11111001 — Multi-Function Pin Control \#22
  [4n-670:4n-672] SCUMUXIO{n} (n=168..175)
0x458 SCU458 reset 0x11111131 — Multi-Function Pin Control \#23
  [4n-702:4n-704] SCUMUXIO{n} (n=176..183)
0x45C SCU45C reset 0x10011111 — Multi-Function Pin Control \#24
  [4n-734:4n-736] SCUMUXIO{n} (n=184..191)
0x460 SCU460 reset 0x10 — Multi-Function Pin Control \#25
  [6:4] SCUMUXIO193, [2:0] SCUMUXIO192
0x480 SCU480 reset 0x2040204 — IO Control \#1
  [25] SCUENHVIO001, [24] SCUENSMTIO001, [23:20] SCUDRVIO001, [18] SCUDISPUIO001, [16] SCUDISPDIO001, [9] SCUENHVIO000, [8] SCUENSMTIO000, [7:4] SCUDRVIO000, [2] SCUDISPUIO000, [0] SCUDISPDIO000
0x484 SCU484 reset 0x2040204 — IO Control \#2
  [25] SCUENHVIO003, [24] SCUENSMTIO003, [23:20] SCUDRVIO003, [18] SCUDISPUIO003, [16] SCUDISPDIO003, [9] SCUENHVIO002, [8] SCUENSMTIO002, [7:4] SCUDRVIO002, [2] SCUDISPUIO002, [0] SCUDISPDIO002
0x488 SCU488 reset 0x2040204 — IO Control \#3
  [25] SCUENHVIO005, [24] SCUENSMTIO005, [23:20] SCUDRVIO005, [18] SCUDISPUIO005, [16] SCUDISPDIO005, [9] SCUENHVIO004, [8] SCUENSMTIO004, [7:4] SCUDRVIO004, [2] SCUDISPUIO004, [0] SCUDISPDIO004
0x48C SCU48C reset 0x2040204 — IO Control \#4
  [25] SCUENHVIO007, [24] SCUENSMTIO007, [23:20] SCUDRVIO007, [18] SCUDISPUIO007, [16] SCUDISPDIO007, [9] SCUENHVIO006, [8] SCUENSMTIO006, [7:4] SCUDRVIO006, [2] SCUDISPUIO006, [0] SCUDISPDIO006
0x490 SCU490 reset 0x2040204 — IO Control \#5
  [25] SCUENHVIO009, [24] SCUENSMTIO009, [23:20] SCUDRVIO009, [18] SCUDISPUIO009, [16] SCUDISPDIO009, [9] SCUENHVIO008, [8] SCUENSMTIO008, [7:4] SCUDRVIO008, [2] SCUDISPUIO008, [0] SCUDISPDIO008
0x494 SCU494 reset 0x2040204 — IO Control \#6
  [25] SCUENHVIO011, [24] SCUENSMTIO011, [23:20] SCUDRVIO011, [18] SCUDISPUIO011, [16] SCUDISPDIO011, [9] SCUENHVIO010, [8] SCUENSMTIO010, [7:4] SCUDRVIO010, [2] SCUDISPUIO010, [0] SCUDISPDIO010
0x498 SCU498 reset 0x2040204 — IO Control \#7
  [25] SCUENHVIO013, [24] SCUENSMTIO013, [23:20] SCUDRVIO013, [18] SCUDISPUIO013, [16] SCUDISPDIO013, [9] SCUENHVIO012, [8] SCUENSMTIO012, [7:4] SCUDRVIO012, [2] SCUDISPUIO012, [0] SCUDISPDIO012
0x49C SCU49C reset 0x2040204 — IO Control \#8
  [25] SCUENHVIO015, [24] SCUENSMTIO015, [23:20] SCUDRVIO015, [18] SCUDISPUIO015, [16] SCUDISPDIO015, [9] SCUENHVIO014, [8] SCUENSMTIO014, [7:4] SCUDRVIO014, [2] SCUDISPUIO014, [0] SCUDISPDIO014
0x4A0 SCU4A0 reset 0x2040204 — IO Control \#9
  [25] SCUENHVIO017, [24] SCUENSMTIO017, [23:20] SCUDRVIO017, [18] SCUDISPUIO017, [16] SCUDISPDIO017, [9] SCUENHVIO016, [8] SCUENSMTIO016, [7:4] SCUDRVIO016, [2] SCUDISPUIO016, [0] SCUDISPDIO016
0x4A4 SCU4A4 reset 0x2040204 — IO Control \#10
  [25] SCUENHVIO019, [24] SCUENSMTIO019, [23:20] SCUDRVIO019, [18] SCUDISPUIO019, [16] SCUDISPDIO019, [9] SCUENHVIO018, [8] SCUENSMTIO018, [7:4] SCUDRVIO018, [2] SCUDISPUIO018, [0] SCUDISPDIO018
0x4A8 SCU4A8 reset 0x2040204 — IO Control \#11
  [25] SCUENHVIO021, [24] SCUENSMTIO021, [23:20] SCUDRVIO021, [18] SCUDISPUIO021, [16] SCUDISPDIO021, [9] SCUENHVIO020, [8] SCUENSMTIO020, [7:4] SCUDRVIO020, [2] SCUDISPUIO020, [0] SCUDISPDIO020
0x4AC SCU4AC reset 0x2040204 — IO Control \#12
  [25] SCUENHVIO023, [24] SCUENSMTIO023, [23:20] SCUDRVIO023, [18] SCUDISPUIO023, [16] SCUDISPDIO023, [9] SCUENHVIO022, [8] SCUENSMTIO022, [7:4] SCUDRVIO022, [2] SCUDISPUIO022, [0] SCUDISPDIO022
0x4B0 SCU4B0 reset 0x2040204 — IO Control \#13
  [25] SCUENHVIO025, [24] SCUENSMTIO025, [23:20] SCUDRVIO025, [18] SCUDISPUIO025, [16] SCUDISPDIO025, [9] SCUENHVIO024, [8] SCUENSMTIO024, [7:4] SCUDRVIO024, [2] SCUDISPUIO024, [0] SCUDISPDIO024
0x4B4 SCU4B4 reset 0x2040204 — IO Control \#14
  [25] SCUENHVIO027, [24] SCUENSMTIO027, [23:20] SCUDRVIO027, [18] SCUDISPUIO027, [16] SCUDISPDIO027, [9] SCUENHVIO026, [8] SCUENSMTIO026, [7:4] SCUDRVIO026, [2] SCUDISPUIO026, [0] SCUDISPDIO026
0x4B8 SCU4B8 reset 0x2040204 — IO Control \#15
  [25] SCUENHVIO029, [24] SCUENSMTIO029, [23:20] SCUDRVIO029, [18] SCUDISPUIO029, [16] SCUDISPDIO029, [9] SCUENHVIO028, [8] SCUENSMTIO028, [7:4] SCUDRVIO028, [2] SCUDISPUIO028, [0] SCUDISPDIO028
0x4BC SCU4BC reset 0x2040204 — IO Control \#16
  [25] SCUENHVIO031, [24] SCUENSMTIO031, [23:20] SCUDRVIO031, [18] SCUDISPUIO031, [16] SCUDISPDIO031, [9] SCUENHVIO030, [8] SCUENSMTIO030, [7:4] SCUDRVIO030, [2] SCUDISPUIO030, [0] SCUDISPDIO030
0x4C0 SCU4C0 reset 0x2040204 — IO Control \#17
  [25] SCUENHVIO033, [24] SCUENSMTIO033, [23:20] SCUDRVIO033, [18] SCUDISPUIO033, [16] SCUDISPDIO033, [9] SCUENHVIO032, [8] SCUENSMTIO032, [7:4] SCUDRVIO032, [2] SCUDISPUIO032, [0] SCUDISPDIO032
0x4C4 SCU4C4 reset 0x2040204 — IO Control \#18
  [25] SCUENHVIO035, [24] SCUENSMTIO035, [23:20] SCUDRVIO035, [18] SCUDISPUIO035, [16] SCUDISPDIO035, [9] SCUENHVIO034, [8] SCUENSMTIO034, [7:4] SCUDRVIO034, [2] SCUDISPUIO034, [0] SCUDISPDIO034
0x4C8 SCU4C8 reset 0x2040204 — IO Control \#19
  [25] SCUENHVIO037, [24] SCUENSMTIO037, [23:20] SCUDRVIO037, [18] SCUDISPUIO037, [16] SCUDISPDIO037, [9] SCUENHVIO036, [8] SCUENSMTIO036, [7:4] SCUDRVIO036, [2] SCUDISPUIO036, [0] SCUDISPDIO036
0x4CC SCU4CC reset 0x2040204 — IO Control \#20
  [25] SCUENHVIO039, [24] SCUENSMTIO039, [23:20] SCUDRVIO039, [18] SCUDISPUIO039, [16] SCUDISPDIO039, [9] SCUENHVIO038, [8] SCUENSMTIO038, [7:4] SCUDRVIO038, [2] SCUDISPUIO038, [0] SCUDISPDIO038
0x4D0 SCU4D0 reset 0x2040204 — IO Control \#21
  [25] SCUENHVIO041, [24] SCUENSMTIO041, [23:20] SCUDRVIO041, [18] SCUDISPUIO041, [16] SCUDISPDIO041, [9] SCUENHVIO040, [8] SCUENSMTIO040, [7:4] SCUDRVIO040, [2] SCUDISPUIO040, [0] SCUDISPDIO040
0x4D4 SCU4D4 reset 0x2040204 — IO Control \#22
  [25] SCUENHVIO043, [24] SCUENSMTIO043, [23:20] SCUDRVIO043, [18] SCUDISPUIO043, [16] SCUDISPDIO043, [9] SCUENHVIO042, [8] SCUENSMTIO042, [7:4] SCUDRVIO042, [2] SCUDISPUIO042, [0] SCUDISPDIO042
0x4D8 SCU4D8 reset 0x2040204 — IO Control \#23
  [25] SCUENHVIO045, [24] SCUENSMTIO045, [23:20] SCUDRVIO045, [18] SCUDISPUIO045, [16] SCUDISPDIO045, [9] SCUENHVIO044, [8] SCUENSMTIO044, [7:4] SCUDRVIO044, [2] SCUDISPUIO044, [0] SCUDISPDIO044
0x4DC SCU4DC reset 0x2040204 — IO Control \#24
  [25] SCUENHVIO047, [24] SCUENSMTIO047, [23:20] SCUDRVIO047, [18] SCUDISPUIO047, [16] SCUDISPDIO047, [9] SCUENHVIO046, [8] SCUENSMTIO046, [7:4] SCUDRVIO046, [2] SCUDISPUIO046, [0] SCUDISPDIO046
0x4E0 SCU4E0 reset 0x2040204 — IO Control \#25
  [25] SCUENHVIO049, [24] SCUENSMTIO049, [23:20] SCUDRVIO049, [18] SCUDISPUIO049, [16] SCUDISPDIO049, [9] SCUENHVIO048, [8] SCUENSMTIO048, [7:4] SCUDRVIO048, [2] SCUDISPUIO048, [0] SCUDISPDIO048
0x4E4 SCU4E4 reset 0x2040204 — IO Control \#26
  [25] SCUENHVIO051, [24] SCUENSMTIO051, [23:20] SCUDRVIO051, [18] SCUDISPUIO051, [16] SCUDISPDIO051, [9] SCUENHVIO050, [8] SCUENSMTIO050, [7:4] SCUDRVIO050, [2] SCUDISPUIO050, [0] SCUDISPDIO050
0x4E8 SCU4E8 reset 0x2040204 — IO Control \#27
  [25] SCUENHVIO053, [24] SCUENSMTIO053, [23:20] SCUDRVIO053, [18] SCUDISPUIO053, [16] SCUDISPDIO053, [9] SCUENHVIO052, [8] SCUENSMTIO052, [7:4] SCUDRVIO052, [2] SCUDISPUIO052, [0] SCUDISPDIO052
0x4EC SCU4EC reset 0x2040204 — IO Control \#28
  [25] SCUENHVIO055, [24] SCUENSMTIO055, [23:20] SCUDRVIO055, [18] SCUDISPUIO055, [16] SCUDISPDIO055, [9] SCUENHVIO054, [8] SCUENSMTIO054, [7:4] SCUDRVIO054, [2] SCUDISPUIO054, [0] SCUDISPDIO054
0x4F0 SCU4F0 reset 0x2040204 — IO Control \#29
  [25] SCUENHVIO057, [24] SCUENSMTIO057, [23:20] SCUDRVIO057, [18] SCUDISPUIO057, [16] SCUDISPDIO057, [9] SCUENHVIO056, [8] SCUENSMTIO056, [7:4] SCUDRVIO056, [2] SCUDISPUIO056, [0] SCUDISPDIO056
0x4F4 SCU4F4 reset 0x2040204 — IO Control \#30
  [25] SCUENHVIO059, [24] SCUENSMTIO059, [23:20] SCUDRVIO059, [18] SCUDISPUIO059, [16] SCUDISPDIO059, [9] SCUENHVIO058, [8] SCUENSMTIO058, [7:4] SCUDRVIO058, [2] SCUDISPUIO058, [0] SCUDISPDIO058
0x4F8 SCU4F8 reset 0x2040204 — IO Control \#31
  [25] SCUENHVIO061, [24] SCUENSMTIO061, [23:20] SCUDRVIO061, [18] SCUDISPUIO061, [16] SCUDISPDIO061, [9] SCUENHVIO060, [8] SCUENSMTIO060, [7:4] SCUDRVIO060, [2] SCUDISPUIO060, [0] SCUDISPDIO060
0x4FC SCU4FC reset 0x2040204 — IO Control \#32
  [25] SCUENHVIO063, [24] SCUENSMTIO063, [23:20] SCUDRVIO063, [18] SCUDISPUIO063, [16] SCUDISPDIO063, [9] SCUENHVIO062, [8] SCUENSMTIO062, [7:4] SCUDRVIO062, [2] SCUDISPUIO062, [0] SCUDISPDIO062
0x500 SCU500 reset 0x2040204 — IO Control \#33
  [25] SCUENHVIO065, [24] SCUENSMTIO065, [23:20] SCUDRVIO065, [18] SCUDISPUIO065, [16] SCUDISPDIO065, [9] SCUENHVIO064, [8] SCUENSMTIO064, [7:4] SCUDRVIO064, [2] SCUDISPUIO064, [0] SCUDISPDIO064
0x504 SCU504 reset 0x2040204 — IO Control \#34
  [25] SCUENHVIO067, [24] SCUENSMTIO067, [23:20] SCUDRVIO067, [18] SCUDISPUIO067, [16] SCUDISPDIO067, [9] SCUENHVIO066, [8] SCUENSMTIO066, [7:4] SCUDRVIO066, [2] SCUDISPUIO066, [0] SCUDISPDIO066
0x508 SCU508 reset 0x2040204 — IO Control \#35
  [25] SCUENHVIO069, [24] SCUENSMTIO069, [23:20] SCUDRVIO069, [18] SCUDISPUIO069, [16] SCUDISPDIO069, [9] SCUENHVIO068, [8] SCUENSMTIO068, [7:4] SCUDRVIO068, [2] SCUDISPUIO068, [0] SCUDISPDIO068
0x50C SCU50C reset 0x2040204 — IO Control \#36
  [25] SCUENHVIO071, [24] SCUENSMTIO071, [23:20] SCUDRVIO071, [18] SCUDISPUIO071, [16] SCUDISPDIO071, [9] SCUENHVIO070, [8] SCUENSMTIO070, [7:4] SCUDRVIO070, [2] SCUDISPUIO070, [0] SCUDISPDIO070
0x510 SCU510 reset 0x2040204 — IO Control \#37
  [25] SCUENHVIO073, [24] SCUENSMTIO073, [23:20] SCUDRVIO073, [18] SCUDISPUIO073, [16] SCUDISPDIO073, [9] SCUENHVIO072, [8] SCUENSMTIO072, [7:4] SCUDRVIO072, [2] SCUDISPUIO072, [0] SCUDISPDIO072
0x514 SCU514 reset 0x2040204 — IO Control \#38
  [25] SCUENHVIO075, [24] SCUENSMTIO075, [23:20] SCUDRVIO075, [18] SCUDISPUIO075, [16] SCUDISPDIO075, [9] SCUENHVIO074, [8] SCUENSMTIO074, [7:4] SCUDRVIO074, [2] SCUDISPUIO074, [0] SCUDISPDIO074
0x518 SCU518 reset 0x2040204 — IO Control \#39
  [25] SCUENHVIO077, [24] SCUENSMTIO077, [23:20] SCUDRVIO077, [18] SCUDISPUIO077, [16] SCUDISPDIO077, [9] SCUENHVIO076, [8] SCUENSMTIO076, [7:4] SCUDRVIO076, [2] SCUDISPUIO076, [0] SCUDISPDIO076
0x51C SCU51C reset 0x2040204 — IO Control \#40
  [25] SCUENHVIO079, [24] SCUENSMTIO079, [23:20] SCUDRVIO079, [18] SCUDISPUIO079, [16] SCUDISPDIO079, [9] SCUENHVIO078, [8] SCUENSMTIO078, [7:4] SCUDRVIO078, [2] SCUDISPUIO078, [0] SCUDISPDIO078
0x520 SCU520 reset 0x2040204 — IO Control \#41
  [25] SCUENHVIO081, [24] SCUENSMTIO081, [23:20] SCUDRVIO081, [18] SCUDISPUIO081, [16] SCUDISPDIO081, [9] SCUENHVIO080, [8] SCUENSMTIO080, [7:4] SCUDRVIO080, [2] SCUDISPUIO080, [0] SCUDISPDIO080
0x524 SCU524 reset 0x2040204 — IO Control \#42
  [25] SCUENHVIO083, [24] SCUENSMTIO083, [23:20] SCUDRVIO083, [18] SCUDISPUIO083, [16] SCUDISPDIO083, [9] SCUENHVIO082, [8] SCUENSMTIO082, [7:4] SCUDRVIO082, [2] SCUDISPUIO082, [0] SCUDISPDIO082
0x528 SCU528 reset 0x2040204 — IO Control \#43
  [25] SCUENHVIO085, [24] SCUENSMTIO085, [23:20] SCUDRVIO085, [18] SCUDISPUIO085, [16] SCUDISPDIO085, [9] SCUENHVIO084, [8] SCUENSMTIO084, [7:4] SCUDRVIO084, [2] SCUDISPUIO084, [0] SCUDISPDIO084
0x52C SCU52C reset 0x2040104 — IO Control \#44
  [25] SCUENHVIO087, [24] SCUENSMTIO087, [23:20] SCUDRVIO087, [18] SCUDISPUIO087, [16] SCUDISPDIO087, [9] SCUENHVIO086, [8] SCUENSMTIO086, [7:4] SCUDRVIO086, [2] SCUDISPUIO086, [0] SCUDISPDIO086
0x530 SCU530 reset 0x2040204 — IO Control \#45
  [25] SCUENHVIO089, [24] SCUENSMTIO089, [23:20] SCUDRVIO089, [18] SCUDISPUIO089, [16] SCUDISPDIO089, [9] SCUENHVIO088, [8] SCUENSMTIO088, [7:4] SCUDRVIO088, [2] SCUDISPUIO088, [0] SCUDISPDIO088
0x534 SCU534 reset 0x2040204 — IO Control \#46
  [25] SCUENHVIO091, [24] SCUENSMTIO091, [23:20] SCUDRVIO091, [18] SCUDISPUIO091, [16] SCUDISPDIO091, [9] SCUENHVIO090, [8] SCUENSMTIO090, [7:4] SCUDRVIO090, [2] SCUDISPUIO090, [0] SCUDISPDIO090
0x538 SCU538 reset 0x2040204 — IO Control \#47
  [25] SCUENHVIO093, [24] SCUENSMTIO093, [23:20] SCUDRVIO093, [18] SCUDISPUIO093, [16] SCUDISPDIO093, [9] SCUENHVIO092, [8] SCUENSMTIO092, [7:4] SCUDRVIO092, [2] SCUDISPUIO092, [0] SCUDISPDIO092
{0x1EC+0x10*i} SCU{i}C reset 0x2040204 (i=53..59) — IO Control \#{4i-164}
  [25] SCUENHVIO{8i-329:03}, [24] SCUENSMTIO{8i-329:03}, [23:20] SCUDRVIO{8i-329:03}, [18] SCUDISPUIO{8i-329:03}, [16] SCUDISPDIO{8i-329:03}, [9] SCUENHVIO{8i-330:03}, [8] SCUENSMTIO{8i-330:03}, [7:4] SCUDRVIO{8i-330:03}, [2] SCUDISPUIO{8i-330:03}, [0] SCUDISPDIO{8i-330:03}
0x540 SCU540 reset 0x2040204 — IO Control \#49
  [25] SCUENHVIO097, [24] SCUENSMTIO097, [23:20] SCUDRVIO097, [18] SCUDISPUIO097, [16] SCUDISPDIO097, [9] SCUENHVIO096, [8] SCUENSMTIO096, [7:4] SCUDRVIO096, [2] SCUDISPUIO096, [0] SCUDISPDIO096
0x544 SCU544 reset 0x2040204 — IO Control \#50
  [25] SCUENHVIO099, [24] SCUENSMTIO099, [23:20] SCUDRVIO099, [18] SCUDISPUIO099, [16] SCUDISPDIO099, [9] SCUENHVIO098, [8] SCUENSMTIO098, [7:4] SCUDRVIO098, [2] SCUDISPUIO098, [0] SCUDISPDIO098
0x548 SCU548 reset 0x2040204 — IO Control \#51
  [25] SCUENHVIO101, [24] SCUENSMTIO101, [23:20] SCUDRVIO101, [18] SCUDISPUIO101, [16] SCUDISPDIO101, [9] SCUENHVIO100, [8] SCUENSMTIO100, [7:4] SCUDRVIO100, [2] SCUDISPUIO100, [0] SCUDISPDIO100
0x550 SCU550 reset 0x2040204 — IO Control \#53
  [25] SCUENHVIO105, [24] SCUENSMTIO105, [23:20] SCUDRVIO105, [18] SCUDISPUIO105, [16] SCUDISPDIO105, [9] SCUENHVIO104, [8] SCUENSMTIO104, [7:4] SCUDRVIO104, [2] SCUDISPUIO104, [0] SCUDISPDIO104
0x554 SCU554 reset 0x2040204 — IO Control \#54
  [25] SCUENHVIO107, [24] SCUENSMTIO107, [23:20] SCUDRVIO107, [18] SCUDISPUIO107, [16] SCUDISPDIO107, [9] SCUENHVIO106, [8] SCUENSMTIO106, [7:4] SCUDRVIO106, [2] SCUDISPUIO106, [0] SCUDISPDIO106
0x558 SCU558 reset 0x2040204 — IO Control \#55
  [25] SCUENHVIO109, [24] SCUENSMTIO109, [23:20] SCUDRVIO109, [18] SCUDISPUIO109, [16] SCUDISPDIO109, [9] SCUENHVIO108, [8] SCUENSMTIO108, [7:4] SCUDRVIO108, [2] SCUDISPUIO108, [0] SCUDISPDIO108
0x560 SCU560 reset 0x2040204 — IO Control \#57
  [25] SCUENHVIO113, [24] SCUENSMTIO113, [23:20] SCUDRVIO113, [18] SCUDISPUIO113, [16] SCUDISPDIO113, [9] SCUENHVIO112, [8] SCUENSMTIO112, [7:4] SCUDRVIO112, [2] SCUDISPUIO112, [0] SCUDISPDIO112
0x564 SCU564 reset 0x2040204 — IO Control \#58
  [25] SCUENHVIO115, [24] SCUENSMTIO115, [23:20] SCUDRVIO115, [18] SCUDISPUIO115, [16] SCUDISPDIO115, [9] SCUENHVIO114, [8] SCUENSMTIO114, [7:4] SCUDRVIO114, [2] SCUDISPUIO114, [0] SCUDISPDIO114
0x568 SCU568 reset 0x2040204 — IO Control \#59
  [25] SCUENHVIO117, [24] SCUENSMTIO117, [23:20] SCUDRVIO117, [18] SCUDISPUIO117, [16] SCUDISPDIO117, [9] SCUENHVIO116, [8] SCUENSMTIO116, [7:4] SCUDRVIO116, [2] SCUDISPUIO116, [0] SCUDISPDIO116
0x570 SCU570 reset 0x2040204 — IO Control \#61
  [25] SCUENHVIO121, [24] SCUENSMTIO121, [23:20] SCUDRVIO121, [18] SCUDISPUIO121, [16] SCUDISPDIO121, [9] SCUENHVIO120, [8] SCUENSMTIO120, [7:4] SCUDRVIO120, [2] SCUDISPUIO120, [0] SCUDISPDIO120
0x574 SCU574 reset 0x2040204 — IO Control \#62
  [25] SCUENHVIO123, [24] SCUENSMTIO123, [23:20] SCUDRVIO123, [18] SCUDISPUIO123, [16] SCUDISPDIO123, [9] SCUENHVIO122, [8] SCUENSMTIO122, [7:4] SCUDRVIO122, [2] SCUDISPUIO122, [0] SCUDISPDIO122
0x578 SCU578 reset 0x2040204 — IO Control \#63
  [25] SCUENHVIO125, [24] SCUENSMTIO125, [23:20] SCUDRVIO125, [18] SCUDISPUIO125, [16] SCUDISPDIO125, [9] SCUENHVIO124, [8] SCUENSMTIO124, [7:4] SCUDRVIO124, [2] SCUDISPUIO124, [0] SCUDISPDIO124
0x580 SCU580 reset 0x2040204 — IO Control \#65
  [25] SCUENHVIO129, [24] SCUENSMTIO129, [23:20] SCUDRVIO129, [18] SCUDISPUIO129, [16] SCUDISPDIO129, [9] SCUENHVIO128, [8] SCUENSMTIO128, [7:4] SCUDRVIO128, [2] SCUDISPUIO128, [0] SCUDISPDIO128
0x584 SCU584 reset 0x2040204 — IO Control \#66
  [25] SCUENHVIO131, [24] SCUENSMTIO131, [23:20] SCUDRVIO131, [18] SCUDISPUIO131, [16] SCUDISPDIO131, [9] SCUENHVIO130, [8] SCUENSMTIO130, [7:4] SCUDRVIO130, [2] SCUDISPUIO130, [0] SCUDISPDIO130
0x588 SCU588 reset 0x2040204 — IO Control \#67
  [25] SCUENHVIO133, [24] SCUENSMTIO133, [23:20] SCUDRVIO133, [18] SCUDISPUIO133, [16] SCUDISPDIO133, [9] SCUENHVIO132, [8] SCUENSMTIO132, [7:4] SCUDRVIO132, [2] SCUDISPUIO132, [0] SCUDISPDIO132
0x590 SCU590 reset 0x2040204 — IO Control \#69
  [25] SCUENHVIO137, [24] SCUENSMTIO137, [23:20] SCUDRVIO137, [18] SCUDISPUIO137, [16] SCUDISPDIO137, [9] SCUENHVIO136, [8] SCUENSMTIO136, [7:4] SCUDRVIO136, [2] SCUDISPUIO136, [0] SCUDISPDIO136
0x594 SCU594 reset 0x2040204 — IO Control \#70
  [25] SCUENHVIO139, [24] SCUENSMTIO139, [23:20] SCUDRVIO139, [18] SCUDISPUIO139, [16] SCUDISPDIO139, [9] SCUENHVIO138, [8] SCUENSMTIO138, [7:4] SCUDRVIO138, [2] SCUDISPUIO138, [0] SCUDISPDIO138
0x598 SCU598 reset 0x2040204 — IO Control \#71
  [25] SCUENHVIO141, [24] SCUENSMTIO141, [23:20] SCUDRVIO141, [18] SCUDISPUIO141, [16] SCUDISPDIO141, [9] SCUENHVIO140, [8] SCUENSMTIO140, [7:4] SCUDRVIO140, [2] SCUDISPUIO140, [0] SCUDISPDIO140
0x5A0 SCU5A0 reset 0x2010201 — IO Control \#73
  [25] SCUENHVIO145, [24] SCUENSMTIO145, [23:20] SCUDRVIO145, [18] SCUDISPUIO145, [16] SCUDISPDIO145, [9] SCUENHVIO144, [8] SCUENSMTIO144, [7:4] SCUDRVIO144, [2] SCUDISPUIO144, [0] SCUDISPDIO144
0x5A4 SCU5A4 reset 0x2040204 — IO Control \#74
  [25] SCUENHVIO147, [24] SCUENSMTIO147, [23:20] SCUDRVIO147, [18] SCUDISPUIO147, [16] SCUDISPDIO147, [9] SCUENHVIO146, [8] SCUENSMTIO146, [7:4] SCUDRVIO146, [2] SCUDISPUIO146, [0] SCUDISPDIO146
0x5A8 SCU5A8 reset 0x2010204 — IO Control \#75
  [25] SCUENHVIO149, [24] SCUENSMTIO149, [23:20] SCUDRVIO149, [18] SCUDISPUIO149, [16] SCUDISPDIO149, [9] SCUENHVIO148, [8] SCUENSMTIO148, [7:4] SCUDRVIO148, [2] SCUDISPUIO148, [0] SCUDISPDIO148
0x5AC SCU5AC reset 0x2010201 — IO Control \#76
  [25] SCUENHVIO151, [24] SCUENSMTIO151, [23:20] SCUDRVIO151, [18] SCUDISPUIO151, [16] SCUDISPDIO151, [9] SCUENHVIO150, [8] SCUENSMTIO150, [7:4] SCUDRVIO150, [2] SCUDISPUIO150, [0] SCUDISPDIO150
0x5B0 SCU5B0 reset 0x2040201 — IO Control \#77
  [25] SCUENHVIO153, [24] SCUENSMTIO153, [23:20] SCUDRVIO153, [18] SCUDISPUIO153, [16] SCUDISPDIO153, [9] SCUENHVIO152, [8] SCUENSMTIO152, [7:4] SCUDRVIO152, [2] SCUDISPUIO152, [0] SCUDISPDIO152
0x5B4 SCU5B4 reset 0x2040204 — IO Control \#78
  [25] SCUENHVIO155, [24] SCUENSMTIO155, [23:20] SCUDRVIO155, [18] SCUDISPUIO155, [16] SCUDISPDIO155, [9] SCUENHVIO154, [8] SCUENSMTIO154, [7:4] SCUDRVIO154, [2] SCUDISPUIO154, [0] SCUDISPDIO154
0x5B8 SCU5B8 reset 0x2010201 — IO Control \#79
  [25] SCUENHVIO157, [24] SCUENSMTIO157, [23:20] SCUDRVIO157, [18] SCUDISPUIO157, [16] SCUDISPDIO157, [9] SCUENHVIO156, [8] SCUENSMTIO156, [7:4] SCUDRVIO156, [2] SCUDISPUIO156, [0] SCUDISPDIO156
0x5BC SCU5BC reset 0x2010201 — IO Control \#80
  [25] SCUENHVIO159, [24] SCUENSMTIO159, [23:20] SCUDRVIO159, [18] SCUDISPUIO159, [16] SCUDISPDIO159, [9] SCUENHVIO158, [8] SCUENSMTIO158, [7:4] SCUDRVIO158, [2] SCUDISPUIO158, [0] SCUDISPDIO158
0x5C0 SCU5C0 reset 0x2040204 — IO Control \#81
  [25] SCUENHVIO161, [24] SCUENSMTIO161, [23:20] SCUDRVIO161, [18] SCUDISPUIO161, [16] SCUDISPDIO161, [9] SCUENHVIO160, [8] SCUENSMTIO160, [7:4] SCUDRVIO160, [2] SCUDISPUIO160, [0] SCUDISPDIO160
0x5C4 SCU5C4 reset 0x2010204 — IO Control \#82
  [25] SCUENHVIO163, [24] SCUENSMTIO163, [23:20] SCUDRVIO163, [18] SCUDISPUIO163, [16] SCUDISPDIO163, [9] SCUENHVIO162, [8] SCUENSMTIO162, [7:4] SCUDRVIO162, [2] SCUDISPUIO162, [0] SCUDISPDIO162
0x5C8 SCU5C8 reset 0x2040201 — IO Control \#83
  [25] SCUENHVIO165, [24] SCUENSMTIO165, [23:20] SCUDRVIO165, [18] SCUDISPUIO165, [16] SCUDISPDIO165, [9] SCUENHVIO164, [8] SCUENSMTIO164, [7:4] SCUDRVIO164, [2] SCUDISPUIO164, [0] SCUDISPDIO164
0x5CC SCU5CC reset 0x2040204 — IO Control \#84
  [25] SCUENHVIO167, [24] SCUENSMTIO167, [23:20] SCUDRVIO167, [18] SCUDISPUIO167, [16] SCUDISPDIO167, [9] SCUENHVIO166, [8] SCUENSMTIO166, [7:4] SCUDRVIO166, [2] SCUDISPUIO166, [0] SCUDISPDIO166
0x5D0 SCU5D0 reset 0x2010204 — IO Control \#85
  [25] SCUENHVIO169, [24] SCUENSMTIO169, [23:20] SCUDRVIO169, [18] SCUDISPUIO169, [16] SCUDISPDIO169, [9] SCUENHVIO168, [8] SCUENSMTIO168, [7:4] SCUDRVIO168, [2] SCUDISPUIO168, [0] SCUDISPDIO168
0x5D4 SCU5D4 reset 0x2040201 — IO Control \#86
  [25] SCUENHVIO171, [24] SCUENSMTIO171, [23:20] SCUDRVIO171, [18] SCUDISPUIO171, [16] SCUDISPDIO171, [9] SCUENHVIO170, [8] SCUENSMTIO170, [7:4] SCUDRVIO170, [2] SCUDISPUIO170, [0] SCUDISPDIO170
0x5D8 SCU5D8 reset 0x2040204 — IO Control \#87
  [25] SCUENHVIO173, [24] SCUENSMTIO173, [23:20] SCUDRVIO173, [18] SCUDISPUIO173, [16] SCUDISPDIO173, [9] SCUENHVIO172, [8] SCUENSMTIO172, [7:4] SCUDRVIO172, [2] SCUDISPUIO172, [0] SCUDISPDIO172
0x5DC SCU5DC reset 0x2040204 — IO Control \#88
  [25] SCUENHVIO175, [24] SCUENSMTIO175, [23:20] SCUDRVIO175, [18] SCUDISPUIO175, [16] SCUDISPDIO175, [9] SCUENHVIO174, [8] SCUENSMTIO174, [7:4] SCUDRVIO174, [2] SCUDISPUIO174, [0] SCUDISPDIO174
0x5E0 SCU5E0 reset 0x2040204 — IO Control \#89
  [25] SCUENHVIO177, [24] SCUENSMTIO177, [23:20] SCUDRVIO177, [18] SCUDISPUIO177, [16] SCUDISPDIO177, [9] SCUENHVIO176, [8] SCUENSMTIO176, [7:4] SCUDRVIO176, [2] SCUDISPUIO176, [0] SCUDISPDIO176
0x5E4 SCU5E4 reset 0x2040204 — IO Control \#90
  [25] SCUENHVIO179, [24] SCUENSMTIO179, [23:20] SCUDRVIO179, [18] SCUDISPUIO179, [16] SCUDISPDIO179, [9] SCUENHVIO178, [8] SCUENSMTIO178, [7:4] SCUDRVIO178, [2] SCUDISPUIO178, [0] SCUDISPDIO178
0x5E8 SCU5E8 reset 0x2040204 — IO Control \#91
  [25] SCUENHVIO181, [24] SCUENSMTIO181, [23:20] SCUDRVIO181, [18] SCUDISPUIO181, [16] SCUDISPDIO181, [9] SCUENHVIO180, [8] SCUENSMTIO180, [7:4] SCUDRVIO180, [2] SCUDISPUIO180, [0] SCUDISPDIO180
0x5EC SCU5EC reset 0x2040204 — IO Control \#92
  [25] SCUENHVIO183, [24] SCUENSMTIO183, [23:20] SCUDRVIO183, [18] SCUDISPUIO183, [16] SCUDISPDIO183, [9] SCUENHVIO182, [8] SCUENSMTIO182, [7:4] SCUDRVIO182, [2] SCUDISPUIO182, [0] SCUDISPDIO182
0x5F0 SCU5F0 reset 0x2040204 — IO Control \#93
  [25] SCUENHVIO185, [24] SCUENSMTIO185, [23:20] SCUDRVIO185, [18] SCUDISPUIO185, [16] SCUDISPDIO185, [9] SCUENHVIO184, [8] SCUENSMTIO184, [7:4] SCUDRVIO184, [2] SCUDISPUIO184, [0] SCUDISPDIO184
0x5F4 SCU5F4 reset 0x2010204 — IO Control \#94
  [25] SCUENHVIO187, [24] SCUENSMTIO187, [23:20] SCUDRVIO187, [18] SCUDISPUIO187, [16] SCUDISPDIO187, [9] SCUENHVIO186, [8] SCUENSMTIO186, [7:4] SCUDRVIO186, [2] SCUDISPUIO186, [0] SCUDISPDIO186
0x5F8 SCU5F8 reset 0x2010201 — IO Control \#95
  [25] SCUENHVIO189, [24] SCUENSMTIO189, [23:20] SCUDRVIO189, [18] SCUDISPUIO189, [16] SCUDISPDIO189, [9] SCUENHVIO188, [8] SCUENSMTIO188, [7:4] SCUDRVIO188, [2] SCUDISPUIO188, [0] SCUDISPDIO188
